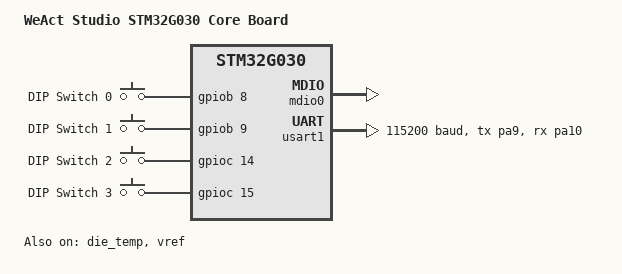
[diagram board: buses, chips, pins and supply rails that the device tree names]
/*
 * Copyright (c) 2026 Albrecht Lohofener
 *
 * SPDX-License-Identifier: Apache-2.0
 */

/dts-v1/;
#include <st/g0/stm32g030X6.dtsi>
#include <st/g0/stm32g030f6px-pinctrl.dtsi>
#include <zephyr/dt-bindings/input/input-event-codes.h>

/ {
	model = "WeAct Studio STM32G030 Core Board";
	compatible = "weact,stm32g030-core";

	chosen {
		zephyr,console = &usart1;
		zephyr,shell-uart = &usart1;
		zephyr,sram = &sram0;
		zephyr,flash = &flash0;
	};

	dip_switches {
        compatible = "gpio-keys";

        dip_0: dip_0 {
            gpios = <&gpiob 8 GPIO_ACTIVE_HIGH>;
            label = "DIP Switch 0";
        };

        dip_1: dip_1 {
            gpios = <&gpiob 9 GPIO_ACTIVE_HIGH>;
            label = "DIP Switch 1";
        };

        dip_2: dip_2 {
            gpios = <&gpioc 14 GPIO_ACTIVE_HIGH>;
            label = "DIP Switch 2";
        };

		dip_3: dip_3 {
            gpios = <&gpioc 15 GPIO_ACTIVE_HIGH>;
            label = "DIP Switch 3";
        };
    };

	aliases {
		dip0 = &dip_0;
		dip1 = &dip_1;
		dip2 = &dip_2;
	};

	mdio0: mdio {
		compatible = "zephyr,mdio-gpio";
		mdc-gpios = <&gpioa 11 GPIO_ACTIVE_HIGH>;
		mdio-gpios = <&gpioa 12 GPIO_ACTIVE_HIGH>;
		status = "okay";
		#address-cells = <1>;
		#size-cells = <0>;
	};
};

&clk_hsi {
	status = "okay";
};


&pll {
	div-m = <1>;
	mul-n = <8>;
	div-r = <2>;
	clocks = <&clk_hsi>;
	status = "okay";
};

&rcc {
	clocks = <&pll>;
	clock-frequency = <DT_FREQ_M(64)>;
	ahb-prescaler = <1>;
	apb1-prescaler = <1>;
};

&usart1 {
	pinctrl-0 = <&usart1_tx_pa9 &usart1_rx_pa10>;
	pinctrl-names = "default";
	current-speed = <115200>;
	status = "okay";
};

&die_temp {
	status = "okay";
};

&flash0 {
	partitions {
		#address-cells = <1>;
		#size-cells = <1>;
		ranges;

		/* Set 4KB of storage at the end of 128KB flash */
		storage_partition: partition@1f000 {
			compatible = "zephyr,mapped-partition";
			label = "storage";
			reg = <0x0001f000 DT_SIZE_K(4)>;
		};
	};
};

&vref {
	status = "okay";
};
